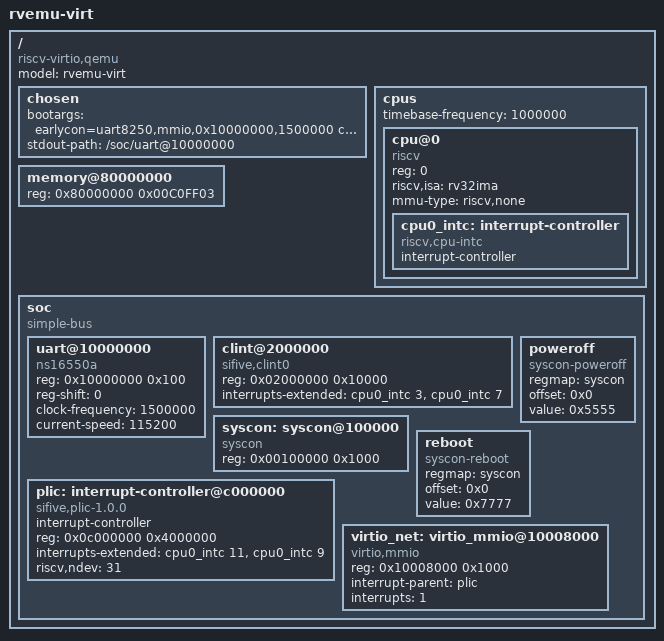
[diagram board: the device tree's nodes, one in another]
/dts-v1/;

/ {
    #address-cells = <1>;
    #size-cells    = <1>;
    compatible     = "riscv-virtio,qemu", "riscv-virtio";
    model          = "rvemu-virt";

    chosen {
        bootargs = "earlycon=uart8250,mmio,0x10000000,1500000 console=ttyS0 root=/dev/ram rw ip=10.0.2.15::10.0.2.2:255.255.255.0::eth0:off";
        stdout-path = "/soc/uart@10000000";
    };

    cpus {
        #address-cells     = <1>;
        #size-cells        = <0>;
        timebase-frequency = <1000000>;

        cpu@0 {
            device_type     = "cpu";
            reg             = <0>;
            status          = "okay";
            compatible      = "riscv";
            riscv,isa       = "rv32ima";
            mmu-type        = "riscv,none";

            cpu0_intc: interrupt-controller {
                #interrupt-cells     = <1>;
                interrupt-controller;
                compatible           = "riscv,cpu-intc";
            };
        };
    };

    /* RAM size patched at runtime by Examples/Linux/Program.cs via the magic
       guard 0x00C0FF03 in the existing DTB. We keep a placeholder here so the
       same patcher works against a freshly-compiled DTB. */
    memory@80000000 {
        device_type = "memory";
        reg         = <0x80000000 0x00C0FF03>;
    };

    soc {
        #address-cells = <1>;
        #size-cells    = <1>;
        compatible     = "simple-bus";
        ranges;

        uart@10000000 {
            compatible      = "ns16550a";
            reg             = <0x10000000 0x100>;
            reg-shift       = <0>;
            clock-frequency = <1500000>;
            current-speed   = <115200>;
        };

        clint@2000000 {
            compatible          = "sifive,clint0", "riscv,clint0";
            reg                 = <0x02000000 0x10000>;
            interrupts-extended = <&cpu0_intc 3 &cpu0_intc 7>;
        };

        syscon: syscon@100000 {
            compatible = "syscon";
            reg        = <0x00100000 0x1000>;
        };

        poweroff {
            compatible = "syscon-poweroff";
            regmap     = <&syscon>;
            offset     = <0x0>;
            value      = <0x5555>;
        };

        reboot {
            compatible = "syscon-reboot";
            regmap     = <&syscon>;
            offset     = <0x0>;
            value      = <0x7777>;
        };

        plic: interrupt-controller@c000000 {
            compatible          = "sifive,plic-1.0.0", "riscv,plic0";
            #interrupt-cells    = <1>;
            interrupt-controller;
            reg                 = <0x0c000000 0x4000000>;
            interrupts-extended = <&cpu0_intc 11 &cpu0_intc 9>;
            riscv,ndev          = <31>;
        };

        virtio_net: virtio_mmio@10008000 {
            compatible      = "virtio,mmio";
            reg             = <0x10008000 0x1000>;
            interrupt-parent = <&plic>;
            interrupts      = <1>;
        };
    };
};
